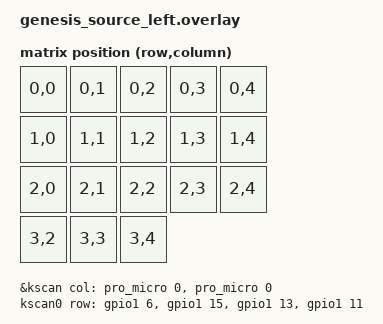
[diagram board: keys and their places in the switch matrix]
// This file was generated from a template. Edit it to match your keyboard.
// See https://zmk.dev/docs/development/hardware-integration/new-shield for more
// instructions.

#include "genesis_source.dtsi"

// Root node configuration
/ {
    chosen {
        zmk,kscan = &kscan0;           // Define key scan configuration
        zmk,matrix_transform = &default_transform;
        zmk,display = &nice_view;      // Point to the display device (nice_view)
    };

    // Keyboard matrix (6x4 left, 5x4 right)
    default_transform: keymap_transform_0 {
        compatible = "zmk,matrix-transform";
        columns = <6>;  // Left half: 6 columns
        rows = <4>;     // Define number of rows
        map = <
            RC(0,0) RC(0,1) RC(0,2) RC(0,3) RC(0,4) 
            RC(1,0) RC(1,1) RC(1,2) RC(1,3) RC(1,4) 
            RC(2,0) RC(2,1) RC(2,2) RC(2,3) RC(2,4) 
            RC(3,2) RC(3,3) RC(3,4)
        >;
    };



&kscan {
    // Replace these comments with the GPIO pins in the matrix for the left side.
    // See https://zmk.dev/docs/development/hardware-integration/new-shield#shield-overlays
    // Keyscan GPIO configuration

    kscan0: kscan {
        compatible = "zmk,kscan-gpio-matrix";
        
        diode-direction = "col2row";  // Set diode direction for the matrix
        row-gpios = <
            &gpio1 6  (GPIO_ACTIVE_HIGH | GPIO_PULL_DOWN)  // Row 0 (P1.06)
            &gpio1 15 (GPIO_ACTIVE_HIGH | GPIO_PULL_DOWN)  // Row 1 (P1.15)
            &gpio1 13 (GPIO_ACTIVE_HIGH | GPIO_PULL_DOWN)  // Row 2 (P1.13)
            &gpio1 11 (GPIO_ACTIVE_HIGH | GPIO_PULL_DOWN)  // Row 3 (P1.11)
        >;
    };

    col-gpios
        = <&pro_micro 0 GPIO_ACTIVE_HIGH>
        , <&pro_micro 0 GPIO_ACTIVE_HIGH>
        ;
};
